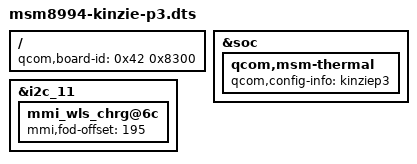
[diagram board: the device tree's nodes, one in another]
/* Copyright (c) 2015, Motorla Mobility LLC. All rights reserved.
 *
 * This program is free software; you can redistribute it and/or modify
 * it under the terms of the GNU General Public License version 2 and
 * only version 2 as published by the Free Software Foundation.
 *
 * This program is distributed in the hope that it will be useful,
 * but WITHOUT ANY WARRANTY; without even the implied warranty of
 * MERCHANTABILITY or FITNESS FOR A PARTICULAR PURPOSE.  See the
 * GNU General Public License for more details.
 */


/dts-v1/;

#include "msm8994-kinzie-v2.1.dtsi"

/ {
	qcom,board-id = <0x42 0x8300>;
};

&soc {
	qcom,msm-thermal {
		qcom,config-info = "kinziep3";
	};
};

&i2c_11 {
	mmi_wls_chrg@6c {
		mmi,fod-offset = <195>;
	};
};
